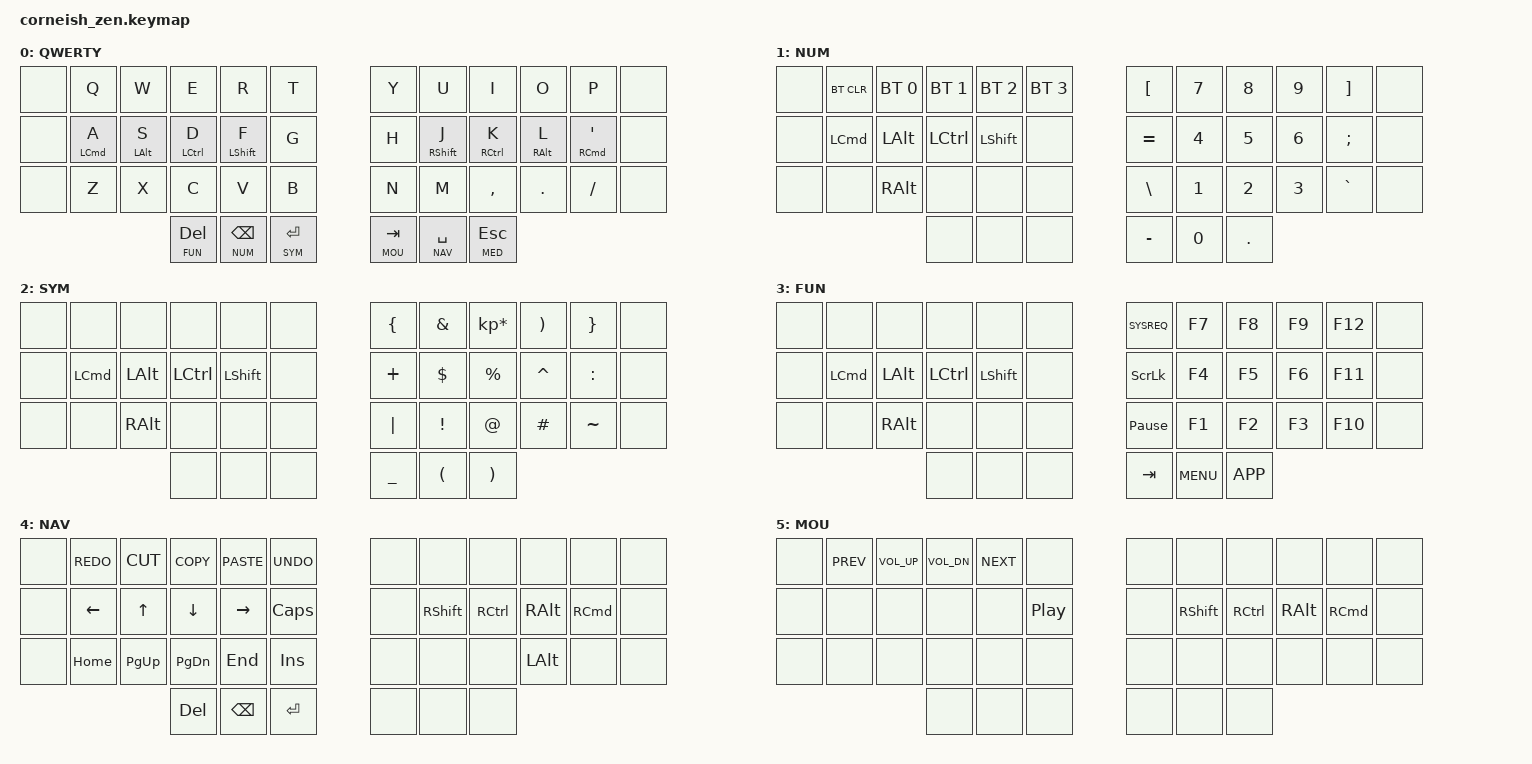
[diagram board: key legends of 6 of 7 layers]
/*
*
* SCHKR MIRYOKU MOD
* Version 1.1
* Copyright (c) 2021 Darryl deHaan
* SPDX-License-Identifier: MIT
*
*/

#include <behaviors.dtsi>
#include <dt-bindings/zmk/keys.h>
#include <dt-bindings/zmk/bt.h>

#define DEFAULT 0
#define NUM 1
#define SYM 2
#define FUN 3
#define NAV 4
#define MOU 5
#define MED 6

&lt {
    quick-tap-ms = <190>;
};

&key_repeat {
    usage-pages = <HID_USAGE_KEY HID_USAGE_CONSUMER>;
};

/ {
  chosen {
    zmk,matrix_transform = &default_transform;
    //zmk,matrix_transform = &five_column_transform;
  };
  behaviors {
    hm: homerow_mods {
      compatible = "zmk,behavior-hold-tap";
      label = "HOMEROW_MODS";
      #binding-cells = <2>;
      flavor = "tap-preferred";
      tapping-term-ms = <190>;
      quick-tap-ms = <190>;
      bindings = <&kp>, <&kp>;
    };
  };
};

/ {
        keymap {
                compatible = "zmk,keymap";
                default_layer {
                        label = "QWERTY";
// ----------------------------------------------------------------------
// |  Q  |  W  |  E  |  R  |  T   |______|  Y  |  U   |  I  |  O  |  P  |
// |  A  |  S  |  D  |  F  |  G   |______|  H  |  J   |  K  |  L  |  ;  |
// |  Z  |  X  |  C  |  V  |  B   |______|  N  |  M   |  ,  |  .  |  /  |
// | DEL/FUN | BSP/NUM | RET/SYM |______| TAB/MOUSE | SPACE/NAV | ESC/MED |
                        bindings = <
    &none  &kp Q  &kp W  &kp E  &kp R  &kp T                           &kp Y  &kp U  &kp I  &kp O  &kp P  &none
    &none  &hm LCMD A  &hm LALT S  &hm LCTRL D  &hm LSHIFT F  &kp G    &kp H  &hm RSHIFT J  &hm RCTRL K  &hm RALT L  &hm RCMD SQT  &none
    &none  &kp Z  &kp X  &kp C  &kp V  &kp B                           &kp N  &kp M  &kp COMMA  &kp DOT  &kp FSLH  &none
    &lt FUN DEL  &lt NUM BSPC  &lt SYM RET                            &lt MOU TAB  &lt NAV SPACE  &lt MED ESC
                        >;
                };

                number_layer {
                        label = "NUM";
// --------------------------------------------------------------
// | BTclr | BT1 | BT2  | BT3  | BT4 |______| [ | 7 | 8 | 9 | ] |
// |  CMD  | ALT | CTRL | SHFT |     |______| = | 4 | 5 | 6 | ; |
// |       | RALT|      |      |     |______| \ | 1 | 2 | 3 | ` |
//               |      |      |     |______| - | 0 | . |
                        bindings = <
    &none  &bt BT_CLR  &bt BT_SEL 0 &bt BT_SEL 1  &bt BT_SEL 2  &bt BT_SEL 3    &kp LBKT  &kp N7  &kp N8  &kp N9  &kp RBKT  &none
    &none  &kp LCMD  &kp LALT  &kp LCTRL  &kp LSHFT  &none                      &kp EQUAL  &kp N4  &kp N5  &kp N6  &kp SEMI  &none
    &none  &none  &kp RALT  &none  &none  &none                                 &kp BSLH  &kp N1  &kp N2  &kp N3  &kp GRAVE  &none
    &none  &none  &none                                                         &kp MINUS  &kp N0  &kp DOT
                        >;
                };

                symbol_layer {
                        label = "SYM";
// ----------------------------------------------------------
// |     |     |      |      |   |______| { | & | * | ) | } |
// | CMD | ALT | CTRL | SHFT |   |______| + | $ | % | ^ | : |
// |     | RALT|      |      |   |______| | | ! | @ | # | ~ |
//             |      |      |   |______| _ | ( | ) |
                        bindings = <
    &none  &none  &none  &none  &none  &none                  &kp LBRC  &kp AMPS  &kp KP_MULTIPLY  &kp RPAR  &kp RBRC  &none
    &none  &kp LCMD  &kp LALT  &kp LCTRL  &kp LSHFT  &none    &kp PLUS  &kp DLLR  &kp PRCNT  &kp CARET  &kp COLON  &none
    &none  &none  &kp RALT  &none  &none  &none               &kp PIPE  &kp EXCL  &kp AT  &kp HASH  &kp TILDE  &none
    &none  &none  &none                                       &kp UNDER  &kp LPAR  &kp RPAR
                        >;
                };

                function_layer {
                        label = "FUN";
// -------------------------------------------------------------------
// |     |     |      |      |   |______|      | F7 | F8 | F9 | F12 |
// | CMD | ALT | CTRL | SHFT |   |______| SCRL | F4 | F5 | F6 | F11 |
// |     | RALT|      |      |   |______| BRK  | F1 | F2 | F3 | F10 |
//             |      |      |   |______| TAB  | SysRq | Fn |
                        bindings = <
    &none  &none  &none  &none  &none  &none                  &kp SYSREQ  &kp F7  &kp F8  &kp F9  &kp F12  &none
    &none  &kp LCMD  &kp LALT  &kp LCTRL  &kp LSHFT  &none    &kp SLCK  &kp F4  &kp F5  &kp F6  &kp F11  &none
    &none  &none  &kp RALT  &none  &none  &none               &kp PAUSE_BREAK  &kp F1  &kp F2  &kp F3  &kp F10  &none
    &none  &none  &none                                       &kp TAB  &kp K_MENU  &kp K_APP
                        >;
                };

                navigation_layer {
                        label = "NAV";
// -----------------------------------------------------------------------------
// | REDO | CUT  | COPY   | PASTE | UNDO |______|    |      |      |     |     |
// | LEFT | UP   | DOWN   | RIGHT | CAPS |______|    | SHFT | CTRL | ALT | CMD |
// | HOME | PGUP | PGDOWN |  END  | INS  |______|    |      |      | LALT|     |
//               |   DEL  | BKSPC | ENT  |______|    |      |      |
                        bindings = <
    &none  &kp K_REDO  &kp K_CUT  &kp K_COPY  &kp K_PASTE  &kp K_UNDO    &none  &none  &none  &none  &none  &none
    &none  &kp LEFT  &kp UP  &kp DOWN  &kp RIGHT  &kp CAPS               &none  &kp RSHFT  &kp RCTRL  &kp RALT  &kp RCMD  &none
    &none  &kp HOME  &kp PG_UP  &kp PG_DN  &kp END  &kp INS              &none  &none  &none  &kp LALT  &none  &none
    &kp DEL  &kp BSPC  &kp RET                                           &none  &none  &none
                        >;
                };

                mouse_layer {
                        label = "MOU";
// ------------------------------------------------------------------------------------
// | PREV | VOL UP | VOL DN | NEXT |            |______|    |      |      |     |     |
// |      |        |        |      | Play/Pause |______|    | SHFT | CTRL | ALT | CMD |
// |      |        |        |      |            |______|    |      |      | LALT|     |
//                 |        |      |            |______|    |      |      |
                        bindings = <
    &none  &kp C_PREV  &kp C_VOL_UP  &kp C_VOL_DN  &kp C_NEXT  &none    &none  &none  &none  &none &none &none
    &none  &none  &none &none &none &kp C_PP                            &none  &kp RSHFT  &kp RCTRL  &kp RALT  &kp RCMD &none
    &none  &none  &none  &none  &none  &none                            &none  &none  &none  &none  &none &none
    &none  &none  &none                                                 &none  &none  &none
                        >;
                };

                media_layer {
                        label = "MED";
// -------------------------------------------------------------------------------------
// | ZoomOut | Scrl Dn | Scrl Up | ZoomIn |      |______|    |      |      |     |     |
// | PREV    | VOL UP  | VOL DN  | NEXT   | PP   |______|    | SHFT | CTRL | ALT | CMD |
// |         |         |         |        |      |______|    |      |      | LALT|     |
//                     |         |        |      |______|    |      |      |
                        bindings = <
    &none  &kp C_AC_ZOOM_OUT  &kp C_AC_SCROLL_UP  &kp C_AC_SCROLL_DOWN  &kp C_AC_ZOOM_IN  &none    &none  &none  &none  &none &none
    &none  &kp C_PREV  &kp C_VOL_UP  &kp C_VOL_DN  &kp C_NEXT  &none                               &none  &kp RSHFT  &kp RCTRL  &kp RALT  &kp RCMD &none
    &none  &none  &none  &none  &none  &none                                                       &none  &none  &none  &none  &none &none
    &kp C_MUTE  &kp C_PP  &kp C_STOP                                                               &none  &none  &none
                        >;
                };
        };
};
